# CH641 register map
Vendor: WCH Ltd.; File version: 1.0
Registers are 32-bit, read-write, reset 0x0 unless marked. A register's access mark holds for its fields unless they carry their own. Offsets are from the block's base; [hi:lo] are bit positions; {n}, {i} and the like mark numbered series.

## EXTEN — Extend configuration
Base 0x40023800
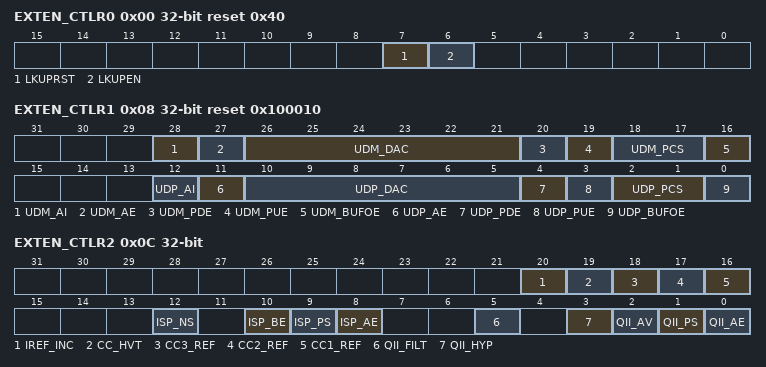
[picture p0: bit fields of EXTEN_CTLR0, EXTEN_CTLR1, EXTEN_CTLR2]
0x00 EXTEN_CTLR0 access per field reset 0x40 — Configure the extended control register 0
  [7] LKUPRST read/clear — LOCKUP RESET
  [6] LKUPEN rw — LOCKUP_Enable
0x08 EXTEN_CTLR1 reset 0x100010 — Configure the extended control register 1
  [28] UDM_AI — Output of the UDM pin comparator DAC_BUF
  [27] UDM_AE — Enable of the UDM pin buffer/comparator DAC_BUF
  [26:21] UDM_DAC — UPM port DAC data/programmable pull-down resistor and pull-up resistor data
  [20] UDM_PDE — UPM port DAC and programmable pull-down and pull-up mode selection
  [19] UDM_PUE — UPM port DAC and programmable pull-down and pull-up mode selection
  [18:17] UDM_PCS — Select pull-up current or pull-down current built into the UDM pin
  [16] UDM_BUFOE — UDM pin DAC_BUF output enable
  [12] UDP_AI — Output of the UDP pin comparator DAC_BUF
  [11] UDP_AE — Enable of the UDP pin buffer/comparator DAC_BUF
  [10:5] UDP_DAC — UPD port DAC data/programmable pull-down resistor and pull-up resistor data
  [4] UDP_PDE — UPD port DAC and programmable pull-down and pull-up mode selection
  [3] UDP_PUE — UPD port DAC and programmable pull-down and pull-up mode selection
  [2:1] UDP_PCS — Select pull-up current or pull-down current built into the UDP pin
  [0] UDP_BUFOE — UDP pin DAC_BUF output enable
0x0C EXTEN_CTLR2 — Configure the extended control register 2
  [20] IREF_INC — Reference current state selection for pins PD PHY and bc
  [19] CC_HVT — CC pin high threshold input mode enabled
  [18] CC3_REF — CC3 pin emulation reference enable
  [17] CC2_REF — CC2 pin emulation reference enable
  [16] CC1_REF — CC1 pin emulation reference enable
  [12] ISP_NS — ISP_OP channel selection at the negative input
  [10] ISP_BE — ISP_OP bias enable
  [9] ISP_PS — ISP_OP channel selection at the positive input
  [8] ISP_AE — ISP_OP enable
  [5] QII_FILT — QII digital filtering enable
  [3] QII_HYP — QII_CMP hysteresis voltage selection
  [2] QII_AV — QII_OP gain select
  [1] QII_PS — QII_OP channel selection at the input
  [0] QII_AE — QII_OP and QII_CMP enable

## GPIOA — General purpose I/O
Base 0x40010800
Same registers: GPIOB 0x40010C00
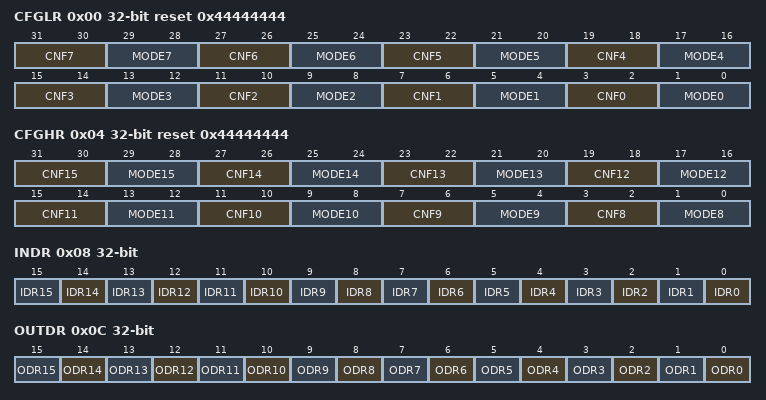
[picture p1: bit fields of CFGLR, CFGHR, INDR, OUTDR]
0x00 CFGLR reset 0x44444444 — Port configuration register low (GPIOn_CFGLR)
  [31:30] CNF7 — Port n.7 configuration bits
  [29:28] MODE7 — Port n.7 mode bits
  [27:26] CNF6 — Port n.6 configuration bits
  [25:24] MODE6 — Port n.6 mode bits
  [23:22] CNF5 — Port n.5 configuration bits
  [21:20] MODE5 — Port n.5 mode bits
  [19:18] CNF4 — Port n.4 configuration bits
  [17:16] MODE4 — Port n.4 mode bits
  [15:14] CNF3 — Port n.3 configuration bits
  [13:12] MODE3 — Port n.3 mode bits
  [11:10] CNF2 — Port n.2 configuration bits
  [9:8] MODE2 — Port n.2 mode bits
  [7:6] CNF1 — Port n.1 configuration bits
  [5:4] MODE1 — Port n.1 mode bits
  [3:2] CNF0 — Port n.0 configuration bits
  [1:0] MODE0 — Port n.0 mode bits
0x04 CFGHR reset 0x44444444 — Port configuration register high (GPIOn_CFGHR)
  [31:30] CNF15 — Port n.15 configuration bits
  [29:28] MODE15 — Port n.15 mode bits
  [27:26] CNF14 — Port n.14 configuration bits
  [25:24] MODE14 — Port n.14 mode bits
  [23:22] CNF13 — Port n.13 configuration bits
  [21:20] MODE13 — Port n.13 mode bits
  [19:18] CNF12 — Port n.12 configuration bits
  [17:16] MODE12 — Port n.12 mode bits
  [15:14] CNF11 — Port n.11 configuration bits
  [13:12] MODE11 — Port n.11 mode bits
  [11:10] CNF10 — Port n.10 configuration bits
  [9:8] MODE10 — Port n.10 mode bits
  [7:6] CNF9 — Port n.9configuration bits
  [5:4] MODE9 — Port n.9 mode bits
  [3:2] CNF8 — Port n.8 configuration bits
  [1:0] MODE8 — Port n.8 mode bits
0x08 INDR ro — Port input data register (GPIOn_INDR)
  [n] IDR{n} (n=0..15) — Port input data
0x0C OUTDR — Port output data register (GPIOn_OUTDR)
  [n] ODR{n} (n=0..15) — Port output data
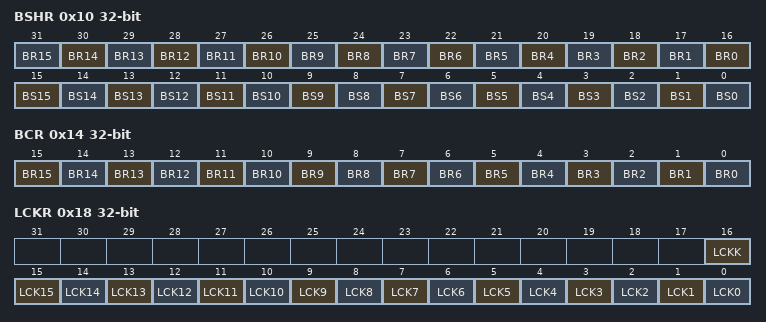
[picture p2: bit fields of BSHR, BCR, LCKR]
0x10 BSHR wo — Port bit set/reset register (GPIOn_BSHR)
  [n+16] BR{n} (n=0..15) — Reset bit {n}
  [n] BS{n} (n=3..15) — Set bit {n}
  [2] BS2 — Set bit 1
  [1] BS1 — Set bit 1
  [0] BS0 — Set bit 0
0x14 BCR wo — Port bit reset register (GPIOn_BCR)
  [n] BR{n} (n=3..15) — Reset bit {n}
  [2] BR2 — Reset bit 1
  [1] BR1 — Reset bit 1
  [0] BR0 — Reset bit 0
0x18 LCKR — Port configuration lock register
  [16] LCKK — Lock key
  [n] LCK{n} (n=0..15) — Port A Lock bit {n}
